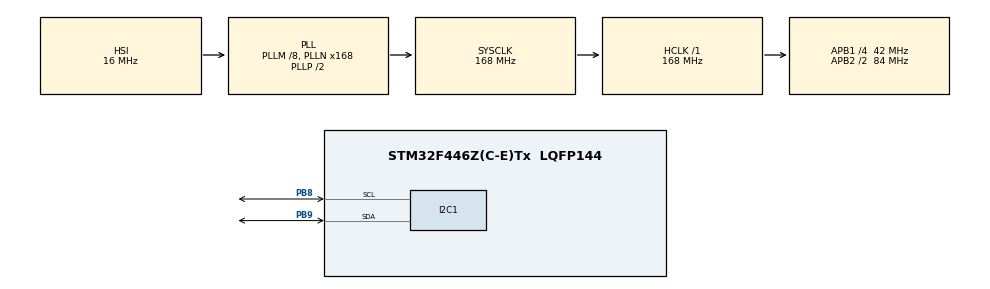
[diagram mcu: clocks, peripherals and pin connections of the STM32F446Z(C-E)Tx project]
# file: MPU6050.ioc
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Mcu.Family=STM32F4
Mcu.Name=STM32F446Z(C-E)Tx
Mcu.Package=LQFP144
NVIC.PriorityGroup=NVIC_PRIORITYGROUP_4
PB8.Mode=I2C
PB8.Signal=I2C1_SCL
PB9.Mode=I2C
PB9.Signal=I2C1_SDA
PH0-OSC_IN.Mode=HSE-External-Oscillator
PH0-OSC_IN.Signal=RCC_OSC_IN
PH1-OSC_OUT.Mode=HSE-External-Oscillator
PH1-OSC_OUT.Signal=RCC_OSC_OUT
ProjectManager.HeapSize=0x200
ProjectManager.StackSize=0x400
ProjectManager.TargetToolchain=STM32CubeIDE
RCC.AHBFreq_Value=168000000
RCC.APB1CLKDivider=RCC_HCLK_DIV4
RCC.APB1Freq_Value=42000000
RCC.APB1TimFreq_Value=84000000
RCC.APB2CLKDivider=RCC_HCLK_DIV2
RCC.APB2Freq_Value=84000000
RCC.APB2TimFreq_Value=168000000
RCC.CortexFreq_Value=168000000
RCC.HCLKFreq_Value=168000000
RCC.HSE_VALUE=8000000
RCC.PLLM=8
RCC.PLLN=168
RCC.SYSCLKFreq_VALUE=168000000
RCC.SYSCLKSource=RCC_SYSCLKSOURCE_PLLCLK
RCC.USBFreq_Value=168000000
RCC.VCOOutputFreq_Value=336000000
board=custom

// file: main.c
/* USER CODE BEGIN Header */
/**
  ******************************************************************************
  * @file           : main.c
  * @brief          : Main program body
  ******************************************************************************
  * @attention
  *
  * Copyright (c) 2025 STMicroelectronics.
  * All rights reserved.
  *
  * This software is licensed under terms that can be found in the LICENSE file
  * in the root directory of this software component.
  * If no LICENSE file comes with this software, it is provided AS-IS.
  *
  ******************************************************************************
  */
/* USER CODE END Header */
#include "main.h"

/* USER CODE BEGIN PD */
#define MPU6050_ADDRESS		0x68<<1

#define MPU6050_CONFIG		0x1A
#define GYRO_CONFIG			0x1B
#define ACCEL_CONFIG		0x1C
#define ACCEL_MSB			0x3B	//	Read until 0x40 -> 48 bits for ACCEL, 6 bytes
#define TEMP_MSB			0x41	//	Read until 0x41 -> 16 bits for Temp
#define GYRO_MSB			0x43
#define RESET_ADDRESS		0x68
#define SMPRT_DIV			0x19
#define PWR_MGMT_1			0x6B

/* USER CODE END PD */

I2C_HandleTypeDef hi2c1;

/* USER CODE BEGIN PV */
uint8_t config = 0x00;
uint8_t smprtDIV = 0x00;
uint8_t gyroConfig = 0x18;
uint8_t accelConfig = 0x18;

int16_t accelX = 0x00;
int16_t accelY = 0x00;
int16_t accelZ = 0x00;

int16_t gyroX = 0x00;
int16_t gyroY = 0x00;
int16_t gyroZ = 0x00;

uint8_t pwrMgnt1 = 0x00;

uint8_t reset = 0x07;
uint8_t address = 0;

float aX;
float aY;
float aZ;

float gX;
float gY;
float gZ;
/* USER CODE uint8_t address = 0;
 * END PV */

void SystemClock_Config(void);
static void MX_GPIO_Init(void);
static void MX_I2C1_Init(void);

/* USER CODE BEGIN 0 */

void MPU6050_Init(void){

	HAL_I2C_Mem_Write(&hi2c1, MPU6050_ADDRESS, PWR_MGMT_1, 1, &pwrMgnt1, 1, HAL_MAX_DELAY);

	HAL_I2C_Mem_Write(&hi2c1, MPU6050_ADDRESS, RESET_ADDRESS, 1, &reset, 1, HAL_MAX_DELAY);

	HAL_I2C_Mem_Write(&hi2c1, MPU6050_ADDRESS, SMPRT_DIV, 1, &smprtDIV, 1, HAL_MAX_DELAY);

	HAL_I2C_Mem_Write(&hi2c1, MPU6050_ADDRESS, MPU6050_CONFIG, 1, &config, 1, HAL_MAX_DELAY);

	HAL_I2C_Mem_Write(&hi2c1, MPU6050_ADDRESS, ACCEL_CONFIG, 1, &accelConfig, 1, HAL_MAX_DELAY);

	HAL_I2C_Mem_Write(&hi2c1, MPU6050_ADDRESS, GYRO_CONFIG, 1, &gyroConfig, 1, HAL_MAX_DELAY);

}

void readAccelData(void){
	uint8_t accelData[6];

	HAL_I2C_Mem_Read(&hi2c1, MPU6050_ADDRESS, ACCEL_MSB, 1, accelData, 6, HAL_MAX_DELAY);

	accelX = ((int16_t)accelData[0] << 8) | (int16_t)accelData[1];
	accelY = ((int16_t)accelData[2] << 8) | (int16_t)accelData[3];
	accelZ = ((int16_t)accelData[4] << 8) | (int16_t)accelData[5];

	aX = (float)accelX/2048.0;
	aY = (float)accelY/2048.0;
	aZ = (float)accelZ/2048.0;

	HAL_Delay(200);
}

void findADDR(){
	for(int i = 0; i <= 255; i++){
		if((HAL_I2C_IsDeviceReady(&hi2c1, i, 1, 10)) == HAL_OK){
			address = i;
			HAL_Delay(200);
		}

	}

}

void readGyroData(void){
	uint8_t gyroData[6];

	HAL_I2C_Mem_Read(&hi2c1, MPU6050_ADDRESS, GYRO_MSB, 1, gyroData, 6, HAL_MAX_DELAY);

	gyroX = ((int16_t)gyroData[0] << 8) | (int16_t)gyroData[1];
	gyroY = ((int16_t)gyroData[2] << 8) | (int16_t)gyroData[3];
	gyroZ = ((int16_t)gyroData[4] << 8) | (int16_t)gyroData[5];

	gX = (float)gyroX/16.4;
	gY = (float)gyroY/16.4;
	gZ = (float)gyroZ/16.4;

	HAL_Delay(200);

}
/* USER CODE END 0 */

int main(void)
{

  /* MCU Configuration--------------------------------------------------------*/

  /* Reset of all peripherals, Initializes the Flash interface and the Systick. */
  HAL_Init();

  /* Configure the system clock */
  SystemClock_Config();

  /* Initialize all configured peripherals */
  MX_GPIO_Init();
  MX_I2C1_Init();
  /* USER CODE BEGIN 2 */
  findADDR();
  MPU6050_Init();
  /* USER CODE END 2 */

  /* Infinite loop */
  while (1)
  {

    /* USER CODE BEGIN 3 */
	  readAccelData();

	  readGyroData();

  }
  /* USER CODE END 3 */
}

void SystemClock_Config(void)
{
  RCC_OscInitTypeDef RCC_OscInitStruct = {0};
  RCC_ClkInitTypeDef RCC_ClkInitStruct = {0};

  /** Configure the main internal regulator output voltage
  */
  __HAL_RCC_PWR_CLK_ENABLE();
  __HAL_PWR_VOLTAGESCALING_CONFIG(PWR_REGULATOR_VOLTAGE_SCALE1);

  /** Initializes the RCC Oscillators according to the specified parameters
  * in the RCC_OscInitTypeDef structure.
  */
  RCC_OscInitStruct.OscillatorType = RCC_OSCILLATORTYPE_HSI;
  RCC_OscInitStruct.HSIState = RCC_HSI_ON;
  RCC_OscInitStruct.HSICalibrationValue = RCC_HSICALIBRATION_DEFAULT;
  RCC_OscInitStruct.PLL.PLLState = RCC_PLL_ON;
  RCC_OscInitStruct.PLL.PLLSource = RCC_PLLSOURCE_HSI;
  RCC_OscInitStruct.PLL.PLLM = 8;
  RCC_OscInitStruct.PLL.PLLN = 168;
  RCC_OscInitStruct.PLL.PLLP = RCC_PLLP_DIV2;
  RCC_OscInitStruct.PLL.PLLQ = 2;
  RCC_OscInitStruct.PLL.PLLR = 2;
  if (HAL_RCC_OscConfig(&RCC_OscInitStruct) != HAL_OK)
  {
    Error_Handler();
  }

  /** Initializes the CPU, AHB and APB buses clocks
  */
  RCC_ClkInitStruct.ClockType = RCC_CLOCKTYPE_HCLK|RCC_CLOCKTYPE_SYSCLK
                              |RCC_CLOCKTYPE_PCLK1|RCC_CLOCKTYPE_PCLK2;
  RCC_ClkInitStruct.SYSCLKSource = RCC_SYSCLKSOURCE_PLLCLK;
  RCC_ClkInitStruct.AHBCLKDivider = RCC_SYSCLK_DIV1;
  RCC_ClkInitStruct.APB1CLKDivider = RCC_HCLK_DIV4;
  RCC_ClkInitStruct.APB2CLKDivider = RCC_HCLK_DIV2;

  if (HAL_RCC_ClockConfig(&RCC_ClkInitStruct, FLASH_LATENCY_5) != HAL_OK)
  {
    Error_Handler();
  }
}

static void MX_I2C1_Init(void)
{

  hi2c1.Instance = I2C1;
  hi2c1.Init.ClockSpeed = 100000;
  hi2c1.Init.DutyCycle = I2C_DUTYCYCLE_2;
  hi2c1.Init.OwnAddress1 = 0;
  hi2c1.Init.AddressingMode = I2C_ADDRESSINGMODE_7BIT;
  hi2c1.Init.DualAddressMode = I2C_DUALADDRESS_DISABLE;
  hi2c1.Init.OwnAddress2 = 0;
  hi2c1.Init.GeneralCallMode = I2C_GENERALCALL_DISABLE;
  hi2c1.Init.NoStretchMode = I2C_NOSTRETCH_DISABLE;
  if (HAL_I2C_Init(&hi2c1) != HAL_OK)
  {
    Error_Handler();
  }

}

static void MX_GPIO_Init(void)
{

  /* GPIO Ports Clock Enable */
  __HAL_RCC_GPIOH_CLK_ENABLE();
  __HAL_RCC_GPIOB_CLK_ENABLE();

}

void Error_Handler(void)
{
  __disable_irq();
  while (1)
  {
  }
}
